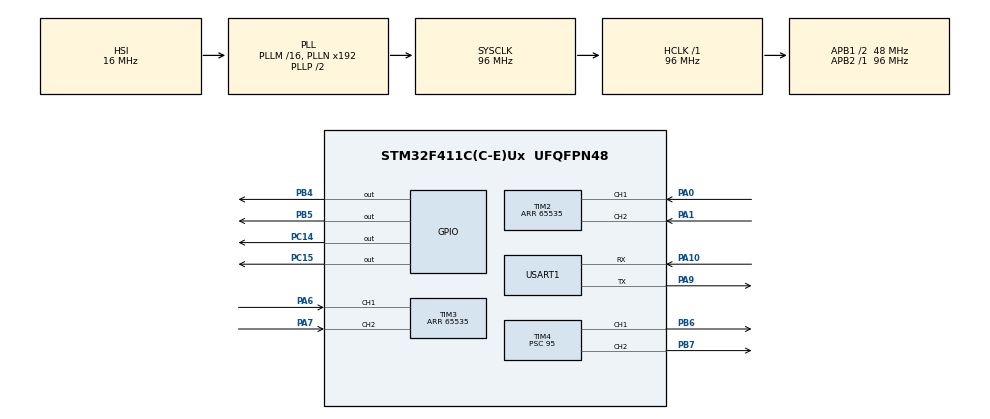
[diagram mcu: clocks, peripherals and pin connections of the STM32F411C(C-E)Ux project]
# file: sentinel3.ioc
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Mcu.Family=STM32F4
Mcu.Name=STM32F411C(C-E)Ux
Mcu.Package=UFQFPN48
NVIC.PriorityGroup=NVIC_PRIORITYGROUP_4
PA0-WKUP.Signal=S_TIM2_CH1_ETR
PA1.Signal=S_TIM2_CH2
PA10.Mode=Asynchronous
PA10.Signal=USART1_RX
PA6.Signal=S_TIM3_CH1
PA7.Signal=S_TIM3_CH2
PA9.Mode=Asynchronous
PA9.Signal=USART1_TX
PB4.Signal=GPIO_Output
PB5.Signal=GPIO_Output
PB6.Signal=S_TIM4_CH1
PB7.Signal=S_TIM4_CH2
PB8.Signal=I2C1_SCL
PB9.Signal=I2C2_SDA
PC14-OSC32_IN.Signal=GPIO_Output
PC15-OSC32_OUT.Signal=GPIO_Output
PH0\ -\ OSC_IN.Mode=HSE-External-Oscillator
PH0\ -\ OSC_IN.Signal=RCC_OSC_IN
PH1\ -\ OSC_OUT.Mode=HSE-External-Oscillator
PH1\ -\ OSC_OUT.Signal=RCC_OSC_OUT
ProjectManager.HeapSize=0x200
ProjectManager.StackSize=0x400
ProjectManager.TargetToolchain=STM32CubeIDE
RCC.AHBFreq_Value=96000000
RCC.APB1CLKDivider=RCC_HCLK_DIV2
RCC.APB1Freq_Value=48000000
RCC.APB1TimFreq_Value=96000000
RCC.APB2Freq_Value=96000000
RCC.APB2TimFreq_Value=96000000
RCC.CortexFreq_Value=96000000
RCC.HCLKFreq_Value=96000000
RCC.HSE_VALUE=25000000
RCC.HSI_VALUE=16000000
RCC.LSE_VALUE=32768
RCC.SYSCLKFreq_VALUE=96000000
RCC.SYSCLKSource=RCC_SYSCLKSOURCE_PLLCLK
RCC.VCOOutputFreq_Value=192000000
SH.S_TIM2_CH1_ETR.0=TIM2_CH1,Encoder_Interface
SH.S_TIM2_CH2.0=TIM2_CH2,Encoder_Interface
SH.S_TIM3_CH1.0=TIM3_CH1,Encoder_Interface
SH.S_TIM3_CH2.0=TIM3_CH2,Encoder_Interface
SH.S_TIM4_CH1.0=TIM4_CH1,PWM Generation1 CH1
SH.S_TIM4_CH2.0=TIM4_CH2,PWM Generation2 CH2
TIM2.EncoderMode=TIM_ENCODERMODE_TI12
TIM2.IC1Filter=5
TIM2.IC2Filter=5
TIM2.Period=65535
TIM3.EncoderMode=TIM_ENCODERMODE_TI12
TIM3.IC1Filter=5
TIM3.IC2Filter=5
TIM3.Period=65535
TIM4.AutoReloadPreload=TIM_AUTORELOAD_PRELOAD_ENABLE
TIM4.Channel-PWM\ Generation1\ CH1=TIM_CHANNEL_1
TIM4.Channel-PWM\ Generation2\ CH2=TIM_CHANNEL_2
TIM4.Period=499
TIM4.Prescaler=95
USART1.VirtualMode=VM_ASYNC
VP_TIM4_VS_ClockSourceINT.Mode=Internal
board=custom

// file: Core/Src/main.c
/* USER CODE BEGIN Header */
/**
  ******************************************************************************
  * @file           : main.c
  * @brief          : Main program body
  ******************************************************************************
  * @attention
  *
  * Copyright (c) 2026 STMicroelectronics.
  * All rights reserved.
  *
  * This software is licensed under terms that can be found in the LICENSE file
  * in the root directory of this software component.
  * If no LICENSE file comes with this software, it is provided AS-IS.
  *
  ******************************************************************************
  */
/* USER CODE END Header */
#include "main.h"
#include <stdio.h>   // untuk sprintf
#include <string.h>

TIM_HandleTypeDef htim2;
TIM_HandleTypeDef htim3;
TIM_HandleTypeDef htim4;

UART_HandleTypeDef huart1;

void SystemClock_Config(void);
static void MX_GPIO_Init(void);
static void MX_TIM2_Init(void);
static void MX_TIM3_Init(void);
static void MX_TIM4_Init(void);
static void MX_USART1_UART_Init(void);
/* USER CODE BEGIN PFP */
static void UART_PrintKikiName(void);
/* USER CODE END PFP */

int main(void)
{

  /* MCU Configuration--------------------------------------------------------*/

  /* Reset of all peripherals, Initializes the Flash interface and the Systick. */
  HAL_Init();

  /* Configure the system clock */
  SystemClock_Config();

  /* Initialize all configured peripherals */
  MX_GPIO_Init();
  MX_TIM2_Init();
  MX_TIM3_Init();
  MX_TIM4_Init();
  MX_USART1_UART_Init();
  /* USER CODE BEGIN 2 */

//  float angleVal1 = 0;
//  float angleVal2 = 0;

  uint32_t counterVal1 = 0;
  uint32_t counterVal2 = 0;
  uint32_t pastCounterVal1 = 0;
  uint32_t pastCounterVal2 = 0;

  char printMsg[100];

  HAL_TIM_Encoder_Start(&htim2, TIM_CHANNEL_ALL);
  HAL_TIM_Encoder_Start(&htim3, TIM_CHANNEL_ALL);

  UART_PrintKikiName();
  /* USER CODE END 2 */

  /* Infinite loop */
  while (1)
  {
	  //	  HAL_GPIO_WritePin(GPIOC, GPIO_PIN_15, 1);
	  //	  HAL_GPIO_WritePin(GPIOC, GPIO_PIN_14, 0);
	  //	  HAL_GPIO_WritePin(GPIOB, GPIO_PIN_5, 1);
	  //	  HAL_GPIO_WritePin(GPIOB, GPIO_PIN_4, 0);
	  //	  TIM4->CCR2 = 250;
	  //	  TIM4->CCR1 = 250;
	  //	  HAL_TIM_PWM_Start(&htim4, TIM_CHANNEL_2);
	  //	  HAL_TIM_PWM_Start(&htim4, TIM_CHANNEL_1);
	  //	  HAL_Delay(5000);
	  	  //end rotate clockwise

	  	  //motor stop
	  //	  HAL_TIM_PWM_Stop(&htim4, TIM_CHANNEL_2);
	  //	  HAL_TIM_PWM_Stop(&htim4, TIM_CHANNEL_1);
	  //	  HAL_Delay(5000);

	    // Read encoder 1
	    counterVal1 = __HAL_TIM_GET_COUNTER(&htim2);
	    if(counterVal1 != pastCounterVal1)
	    {
	        sprintf(printMsg, "ENC1: %lu\r\n", counterVal1);
	        HAL_UART_Transmit(&huart1, (uint8_t*)printMsg, strlen(printMsg), 100);
	        pastCounterVal1 = counterVal1;
	    }

	    // Read encoder 2
	    counterVal2 = __HAL_TIM_GET_COUNTER(&htim3);
	    if(counterVal2 != pastCounterVal2)
	    {
	        sprintf(printMsg, "ENC2: %lu\r\n", counterVal2);
	        HAL_UART_Transmit(&huart1, (uint8_t*)printMsg, strlen(printMsg), 100);
	        pastCounterVal2 = counterVal2;
	    }

	    HAL_Delay(10);

	  	  //start rotate counterclockwise
	  //	  HAL_GPIO_WritePin(GPIOC, GPIO_PIN_15, 0);
	  //	  HAL_GPIO_WritePin(GPIOC, GPIO_PIN_14, 1);
	  //	  HAL_GPIO_WritePin(GPIOB, GPIO_PIN_5, 0);
	  //	  HAL_GPIO_WritePin(GPIOB, GPIO_PIN_4, 1);
	  //	  TIM4->CCR2 = 300;
	  //	  TIM4->CCR1 = 499;
	  //	  HAL_TIM_PWM_Start(&htim4, TIM_CHANNEL_2);
	  //	  HAL_TIM_PWM_Start(&htim4, TIM_CHANNEL_1);
	  //	  HAL_Delay(5000);
	  	  //stop rotate counterclockwise

	  	  //stop motor
	  //	  HAL_TIM_PWM_Stop(&htim4, TIM_CHANNEL_2);
	  //	  HAL_TIM_PWM_Stop(&htim4, TIM_CHANNEL_1);
	  //	  HAL_Delay(5000);
  }
}

void SystemClock_Config(void)
{
  RCC_OscInitTypeDef RCC_OscInitStruct = {0};
  RCC_ClkInitTypeDef RCC_ClkInitStruct = {0};

  /** Configure the main internal regulator output voltage
  */
  __HAL_RCC_PWR_CLK_ENABLE();
  __HAL_PWR_VOLTAGESCALING_CONFIG(PWR_REGULATOR_VOLTAGE_SCALE1);

  /** Initializes the RCC Oscillators according to the specified parameters
  * in the RCC_OscInitTypeDef structure.
  */
  RCC_OscInitStruct.OscillatorType = RCC_OSCILLATORTYPE_HSI;
  RCC_OscInitStruct.HSIState = RCC_HSI_ON;
  RCC_OscInitStruct.HSICalibrationValue = RCC_HSICALIBRATION_DEFAULT;
  RCC_OscInitStruct.PLL.PLLState = RCC_PLL_ON;
  RCC_OscInitStruct.PLL.PLLSource = RCC_PLLSOURCE_HSI;
  RCC_OscInitStruct.PLL.PLLM = 16;
  RCC_OscInitStruct.PLL.PLLN = 192;
  RCC_OscInitStruct.PLL.PLLP = RCC_PLLP_DIV2;
  RCC_OscInitStruct.PLL.PLLQ = 4;
  if (HAL_RCC_OscConfig(&RCC_OscInitStruct) != HAL_OK)
  {
    Error_Handler();
  }

  /** Initializes the CPU, AHB and APB buses clocks
  */
  RCC_ClkInitStruct.ClockType = RCC_CLOCKTYPE_HCLK|RCC_CLOCKTYPE_SYSCLK
                              |RCC_CLOCKTYPE_PCLK1|RCC_CLOCKTYPE_PCLK2;
  RCC_ClkInitStruct.SYSCLKSource = RCC_SYSCLKSOURCE_PLLCLK;
  RCC_ClkInitStruct.AHBCLKDivider = RCC_SYSCLK_DIV1;
  RCC_ClkInitStruct.APB1CLKDivider = RCC_HCLK_DIV2;
  RCC_ClkInitStruct.APB2CLKDivider = RCC_HCLK_DIV1;

  if (HAL_RCC_ClockConfig(&RCC_ClkInitStruct, FLASH_LATENCY_3) != HAL_OK)
  {
    Error_Handler();
  }
}

static void MX_TIM2_Init(void)
{

  TIM_Encoder_InitTypeDef sConfig = {0};
  TIM_MasterConfigTypeDef sMasterConfig = {0};

  htim2.Instance = TIM2;
  htim2.Init.Prescaler = 0;
  htim2.Init.CounterMode = TIM_COUNTERMODE_UP;
  htim2.Init.Period = 65535;
  htim2.Init.ClockDivision = TIM_CLOCKDIVISION_DIV1;
  htim2.Init.AutoReloadPreload = TIM_AUTORELOAD_PRELOAD_DISABLE;
  sConfig.EncoderMode = TIM_ENCODERMODE_TI12;
  sConfig.IC1Polarity = TIM_ICPOLARITY_RISING;
  sConfig.IC1Selection = TIM_ICSELECTION_DIRECTTI;
  sConfig.IC1Prescaler = TIM_ICPSC_DIV1;
  sConfig.IC1Filter = 5;
  sConfig.IC2Polarity = TIM_ICPOLARITY_RISING;
  sConfig.IC2Selection = TIM_ICSELECTION_DIRECTTI;
  sConfig.IC2Prescaler = TIM_ICPSC_DIV1;
  sConfig.IC2Filter = 5;
  if (HAL_TIM_Encoder_Init(&htim2, &sConfig) != HAL_OK)
  {
    Error_Handler();
  }
  sMasterConfig.MasterOutputTrigger = TIM_TRGO_RESET;
  sMasterConfig.MasterSlaveMode = TIM_MASTERSLAVEMODE_DISABLE;
  if (HAL_TIMEx_MasterConfigSynchronization(&htim2, &sMasterConfig) != HAL_OK)
  {
    Error_Handler();
  }

}

static void MX_TIM3_Init(void)
{

  TIM_Encoder_InitTypeDef sConfig = {0};
  TIM_MasterConfigTypeDef sMasterConfig = {0};

  htim3.Instance = TIM3;
  htim3.Init.Prescaler = 0;
  htim3.Init.CounterMode = TIM_COUNTERMODE_UP;
  htim3.Init.Period = 65535;
  htim3.Init.ClockDivision = TIM_CLOCKDIVISION_DIV1;
  htim3.Init.AutoReloadPreload = TIM_AUTORELOAD_PRELOAD_DISABLE;
  sConfig.EncoderMode = TIM_ENCODERMODE_TI12;
  sConfig.IC1Polarity = TIM_ICPOLARITY_RISING;
  sConfig.IC1Selection = TIM_ICSELECTION_DIRECTTI;
  sConfig.IC1Prescaler = TIM_ICPSC_DIV1;
  sConfig.IC1Filter = 5;
  sConfig.IC2Polarity = TIM_ICPOLARITY_RISING;
  sConfig.IC2Selection = TIM_ICSELECTION_DIRECTTI;
  sConfig.IC2Prescaler = TIM_ICPSC_DIV1;
  sConfig.IC2Filter = 5;
  if (HAL_TIM_Encoder_Init(&htim3, &sConfig) != HAL_OK)
  {
    Error_Handler();
  }
  sMasterConfig.MasterOutputTrigger = TIM_TRGO_RESET;
  sMasterConfig.MasterSlaveMode = TIM_MASTERSLAVEMODE_DISABLE;
  if (HAL_TIMEx_MasterConfigSynchronization(&htim3, &sMasterConfig) != HAL_OK)
  {
    Error_Handler();
  }

}

static void MX_TIM4_Init(void)
{

  TIM_ClockConfigTypeDef sClockSourceConfig = {0};
  TIM_MasterConfigTypeDef sMasterConfig = {0};
  TIM_OC_InitTypeDef sConfigOC = {0};

  htim4.Instance = TIM4;
  htim4.Init.Prescaler = 95;
  htim4.Init.CounterMode = TIM_COUNTERMODE_UP;
  htim4.Init.Period = 499;
  htim4.Init.ClockDivision = TIM_CLOCKDIVISION_DIV1;
  htim4.Init.AutoReloadPreload = TIM_AUTORELOAD_PRELOAD_ENABLE;
  if (HAL_TIM_Base_Init(&htim4) != HAL_OK)
  {
    Error_Handler();
  }
  sClockSourceConfig.ClockSource = TIM_CLOCKSOURCE_INTERNAL;
  if (HAL_TIM_ConfigClockSource(&htim4, &sClockSourceConfig) != HAL_OK)
  {
    Error_Handler();
  }
  if (HAL_TIM_PWM_Init(&htim4) != HAL_OK)
  {
    Error_Handler();
  }
  sMasterConfig.MasterOutputTrigger = TIM_TRGO_RESET;
  sMasterConfig.MasterSlaveMode = TIM_MASTERSLAVEMODE_DISABLE;
  if (HAL_TIMEx_MasterConfigSynchronization(&htim4, &sMasterConfig) != HAL_OK)
  {
    Error_Handler();
  }
  sConfigOC.OCMode = TIM_OCMODE_PWM1;
  sConfigOC.Pulse = 0;
  sConfigOC.OCPolarity = TIM_OCPOLARITY_HIGH;
  sConfigOC.OCFastMode = TIM_OCFAST_DISABLE;
  if (HAL_TIM_PWM_ConfigChannel(&htim4, &sConfigOC, TIM_CHANNEL_1) != HAL_OK)
  {
    Error_Handler();
  }
  if (HAL_TIM_PWM_ConfigChannel(&htim4, &sConfigOC, TIM_CHANNEL_2) != HAL_OK)
  {
    Error_Handler();
  }
  HAL_TIM_MspPostInit(&htim4);

}

static void MX_USART1_UART_Init(void)
{

  huart1.Instance = USART1;
  huart1.Init.BaudRate = 115200;
  huart1.Init.WordLength = UART_WORDLENGTH_8B;
  huart1.Init.StopBits = UART_STOPBITS_1;
  huart1.Init.Parity = UART_PARITY_NONE;
  huart1.Init.Mode = UART_MODE_TX_RX;
  huart1.Init.HwFlowCtl = UART_HWCONTROL_NONE;
  huart1.Init.OverSampling = UART_OVERSAMPLING_16;
  if (HAL_UART_Init(&huart1) != HAL_OK)
  {
    Error_Handler();
  }

}

static void MX_GPIO_Init(void)
{
  GPIO_InitTypeDef GPIO_InitStruct = {0};

  /* GPIO Ports Clock Enable */
  __HAL_RCC_GPIOC_CLK_ENABLE();
  __HAL_RCC_GPIOH_CLK_ENABLE();
  __HAL_RCC_GPIOA_CLK_ENABLE();
  __HAL_RCC_GPIOB_CLK_ENABLE();

  /*Configure GPIO pin Output Level */
  HAL_GPIO_WritePin(GPIOC, GPIO_PIN_14|GPIO_PIN_15, GPIO_PIN_RESET);

  /*Configure GPIO pin Output Level */
  HAL_GPIO_WritePin(GPIOB, GPIO_PIN_4|GPIO_PIN_5, GPIO_PIN_RESET);

  /*Configure GPIO pins : PC14 PC15 */
  GPIO_InitStruct.Pin = GPIO_PIN_14|GPIO_PIN_15;
  GPIO_InitStruct.Mode = GPIO_MODE_OUTPUT_PP;
  GPIO_InitStruct.Pull = GPIO_NOPULL;
  GPIO_InitStruct.Speed = GPIO_SPEED_FREQ_LOW;
  HAL_GPIO_Init(GPIOC, &GPIO_InitStruct);

  /*Configure GPIO pins : PB4 PB5 */
  GPIO_InitStruct.Pin = GPIO_PIN_4|GPIO_PIN_5;
  GPIO_InitStruct.Mode = GPIO_MODE_OUTPUT_PP;
  GPIO_InitStruct.Pull = GPIO_NOPULL;
  GPIO_InitStruct.Speed = GPIO_SPEED_FREQ_LOW;
  HAL_GPIO_Init(GPIOB, &GPIO_InitStruct);

  /*Configure GPIO pin : PB8 */
  GPIO_InitStruct.Pin = GPIO_PIN_8;
  GPIO_InitStruct.Mode = GPIO_MODE_AF_OD;
  GPIO_InitStruct.Pull = GPIO_NOPULL;
  GPIO_InitStruct.Speed = GPIO_SPEED_FREQ_VERY_HIGH;
  GPIO_InitStruct.Alternate = GPIO_AF4_I2C1;
  HAL_GPIO_Init(GPIOB, &GPIO_InitStruct);

  /*Configure GPIO pin : PB9 */
  GPIO_InitStruct.Pin = GPIO_PIN_9;
  GPIO_InitStruct.Mode = GPIO_MODE_AF_OD;
  GPIO_InitStruct.Pull = GPIO_NOPULL;
  GPIO_InitStruct.Speed = GPIO_SPEED_FREQ_VERY_HIGH;
  GPIO_InitStruct.Alternate = GPIO_AF9_I2C2;
  HAL_GPIO_Init(GPIOB, &GPIO_InitStruct);

}

/* USER CODE BEGIN 4 */
static void UART_PrintKikiName(void)
{
  const char msg[] = "kiki fachrizi\r\n";
  HAL_UART_Transmit(&huart1, (uint8_t *)msg, sizeof(msg) - 1U, 100);
}
/* USER CODE END 4 */

void Error_Handler(void)
{
  __disable_irq();
  while (1)
  {
  }
}
